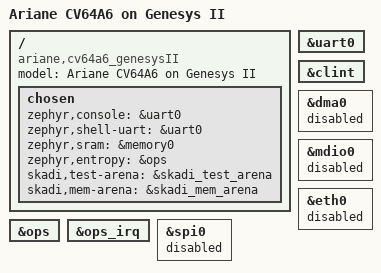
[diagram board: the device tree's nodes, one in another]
/*
 * Copyright (c) 2023 by Rivos Inc.
 *
 * SPDX-License-Identifier: Apache-2.0
 */
/dts-v1/;

#include <openhwgroup/cv64a6.dtsi>

/ {
	model = "Ariane CV64A6 on Genesys II";
	compatible = "ariane,cv64a6_genesysII";

	chosen {
		zephyr,console = &uart0;
		zephyr,shell-uart = &uart0;
		zephyr,sram = &memory0;
		zephyr,entropy=&ops;
		skadi,test-arena = &skadi_test_arena;
		skadi,mem-arena = &skadi_mem_arena;
	};
};

&uart0 {
	status = "okay";
};


&clint{
  status = "okay";
};


&dma0 {
	status = "disabled";
};



&mdio0{
	status = "disabled";
};

&eth0 {
	status = "disabled";
};

&ops {
	status = "okay";
};

&ops_irq {
	status = "okay";
};

/* not simulated */
&spi0 {
	status = "disabled";
};
